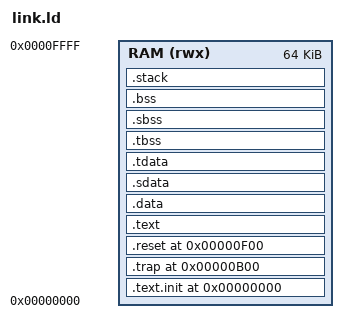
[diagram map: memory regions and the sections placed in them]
/*
* Copyright by Syntacore LLC © 2016, 2017. See LICENSE for details
* @file       <link.ld>
* @brief      bare metal tests' linker script
*/

/* Указать компоновщику целевую архитектуру RISC-V. */
OUTPUT_ARCH( "riscv" )
/* Записать _start в поле точки входа ELF; аппаратный Reset Vector задаётся отдельно в RTL. */
ENTRY(_start)

/* Начало описания доступных областей памяти. */
MEMORY {
  /* Область RAM с чтением, записью и исполнением: начало 0, размер 64 КиБ. */
  RAM (rwx) : ORIGIN = 0x0, LENGTH = 64K
/* Закончить блок. */
}

/* Зарезервировать под стек 1024 байта. */
STACK_SIZE = 1024;

/* Единица выравнивания границ секций: 32 байта. */
CL_SIZE = 32;

/* Начало правил размещения входных секций в выходном ELF. */
SECTIONS {

  /* code segment */
  /* Разместить служебный код остановки с выходной секцией, начинающейся по адресу 0. */
  .text.init 0 : { 
    /* Заполнять промежутки этой секции нулевыми байтами. */
    FILL(0);
    /* Переместить позицию на 0xF4: начало служебного кода завершения симуляции. */
    . = 0x100 - 12;
    /* Символ входа в служебный код выхода, используемый процедурой sc_exit. */
    SIM_EXIT = .;
    /* Разместить 32-битную инструкцию nop: addi x0, x0, 0. */
    LONG(0x13);
    /* Символ адреса 0xF8, распознаваемого тестовым окружением как остановка. */
    SIM_STOP = .;
    /* Разместить 32-битную инструкцию бесконечного перехода на себя. */
    LONG(0x6F);
    /* Разместить 32-битное слово 0xFFFFFFFF после служебной точки остановки. */
    LONG(-1);
  /* Закончить блок; разместить его в RAM. */
  } >RAM

  /* Exception entry and reset entry have fixed hardware addresses. */
  /* Разместить обработчик исключений по фиксированному адресу 0xB00. */
  .trap 0xB00 : {
    /* Предоставить символ __TEXT_START__, если он не задан иначе: начало кода с обработчика по адресу 0xB00. */
    PROVIDE(__TEXT_START__ = .);
    /* Сохранить указанную входную секцию даже при удалении неиспользуемого кода компоновщиком. */
    KEEP(*(.text.trap))
  /* Закончить блок; разместить его в RAM. */
  } >RAM

  /* Разместить стартовый код по фиксированному адресу 0xF00. */
  .reset 0xF00 : {
    /* Сохранить указанную входную секцию даже при удалении неиспользуемого кода компоновщиком. */
    KEEP(*(.text.reset))
    *(.text.init)
  /* Закончить блок; разместить его в RAM. */
  } >RAM

  /* Разместить остальной исполняемый код после стартовой секции. */
  .text  : {
    *crt.o(.text .text.*)
    *(.text .text.*)
    *(sc_test_section)
    /* Округлить текущую позицию вверх до границы CL_SIZE (32 байта). */
    . = ALIGN(CL_SIZE);
     /* Предоставить символ __TEXT_END__, если он не задан иначе: конец обычного кода после выравнивания. */
     PROVIDE(__TEXT_END__ = .);
  /* Закончить блок; разместить его в RAM. */
  } >RAM 

  /* data segment */
  /* Разместить инициализированные изменяемые данные. */
  .data : {
    *(.data .data.*)
    /* Округлить текущую позицию вверх до границы CL_SIZE (32 байта). */
    . = ALIGN(CL_SIZE);
  /* Закончить блок; разместить его в RAM. */
  } >RAM

  /* Разместить малые инициализированные данные и базу gp. */
  .sdata : {
    /* Задать базу gp для доступа к малым данным: текущий адрес плюс 0x800. */
    __global_pointer$ = . + 0x800;
    *(.srodata.cst16) *(.srodata.cst8) *(.srodata.cst4) *(.srodata.cst2) *(.srodata*)
    *(.sdata .sdata.* .gnu.linkonce.s.*)
    /* Округлить текущую позицию вверх до границы CL_SIZE (32 байта). */
    . = ALIGN(CL_SIZE);
  /* Закончить блок; разместить его в RAM. */
  } >RAM

  /* thread-local data segment */
  /* Разместить инициализированные данные локального хранилища потока. */
  .tdata : {
    /* Предоставить символ _tls_data, если он не задан иначе: начало инициализированных данных локального хранилища потока. */
    PROVIDE(_tls_data = .);
    /* Предоставить символ _tdata_begin, если он не задан иначе: начало секции .tdata. */
    PROVIDE(_tdata_begin = .);
    *(.tdata .tdata.*)
    /* Предоставить символ _tdata_end, если он не задан иначе: конец секции .tdata до выравнивания. */
    PROVIDE(_tdata_end = .);
    /* Округлить текущую позицию вверх до границы CL_SIZE (32 байта). */
    . = ALIGN(CL_SIZE);
  /* Закончить блок; разместить его в RAM. */
  } >RAM

  /* Разместить неинициализированные данные локального хранилища потока. */
  .tbss : {
    /* Предоставить символ __BSS_START__, если он не задан иначе: начало неинициализированных данных, начиная с .tbss. */
    PROVIDE(__BSS_START__ = .);
    *(.tbss .tbss.*)
    /* Округлить текущую позицию вверх до границы CL_SIZE (32 байта). */
    . = ALIGN(CL_SIZE);
    /* Предоставить символ _tbss_end, если он не задан иначе: конец секции .tbss после выравнивания. */
    PROVIDE(_tbss_end = .);
  /* Закончить блок; разместить его в RAM. */
  } >RAM

  /* bss segment */
  /* Разместить малые неинициализированные данные. */
  .sbss : {
    *(.sbss .sbss.* .gnu.linkonce.sb.*)
    *(.scommon)
  /* Закончить блок; разместить его в RAM. */
  } >RAM

  /* Разместить остальные неинициализированные данные. */
  .bss : {
    *(.bss .bss.*)
    /* Округлить текущую позицию вверх до границы CL_SIZE (32 байта). */
    . = ALIGN(CL_SIZE);
    /* Предоставить символ __BSS_END__, если он не задан иначе: конец неинициализированных данных. */
    PROVIDE(__BSS_END__ = .);
  /* Закончить блок; разместить его в RAM. */
  } >RAM

  /* Обозначить концом данных адрес после секций BSS; стек размещается отдельно. */
  _end = .;
  /* Предоставить символ __end, если он не задан иначе: конец области данных. */
  PROVIDE(__end = .);

  /* End of uninitalized data segement */

  /* Разместить стек в последних STACK_SIZE байтах RAM. */
  .stack ORIGIN(RAM) + LENGTH(RAM) - STACK_SIZE : {
    /* Заполнять промежутки этой секции нулевыми байтами. */
    FILL(0);
    /* Предоставить символ __STACK_START__, если он не задан иначе: нижнюю границу стека. */
    PROVIDE(__STACK_START__ = .);
    /* Продвинуть позицию на STACK_SIZE байт, выделяя место под стек. */
    . += STACK_SIZE;
    /* Предоставить символ __C_STACK_TOP__, если он не задан иначе: верхнюю границу стека, от которой он растёт вниз. */
    PROVIDE(__C_STACK_TOP__ = .);
    /* Предоставить символ __STACK_END__, если он не задан иначе: конец зарезервированной области стека. */
    PROVIDE(__STACK_END__ = .);
  /* Закончить блок; разместить его в RAM. */
  } >RAM

  /* Перечисленные входные секции исключить из итогового ELF. */
  /DISCARD/ : {
    *(.eh_frame .eh_frame.*)
  /* Закончить блок. */
  }
/* Закончить блок. */
}
